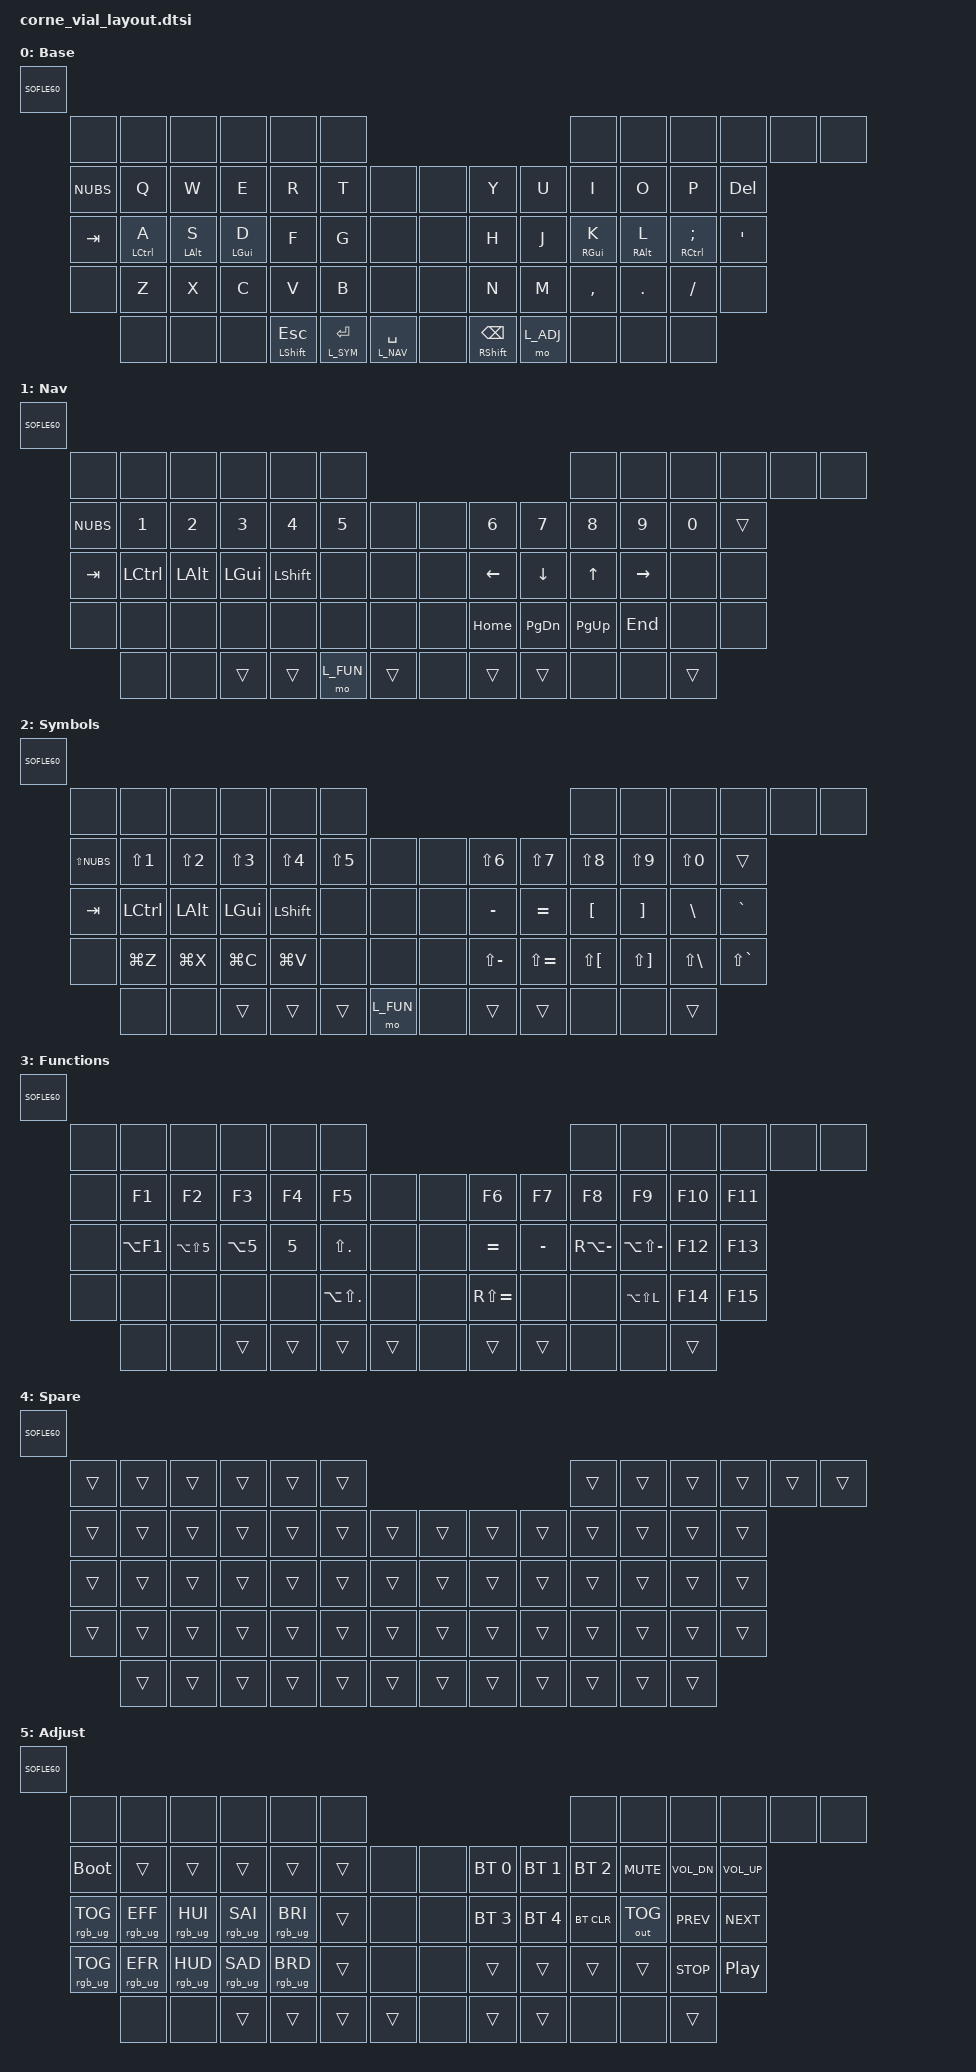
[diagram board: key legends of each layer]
/*
 * Port du keymap Corne 42 Vial (QMK) vers Sofle Choc Pro BT (ZMK).
 * Source : vial-qmk/keyboards/crkbd/keymaps/vial/keymap.c
 *
 * Matrice Sofle 60 avec 42 positions actives (switches Corne) ; le reste en &none.
 * Layout Townk conservé dans standard_layout.dtsi pour y revenir.
 *
 * TODO : réactiver souris — décommenter les includes mouse/homerowmods/specialkeys
 *        et brancher une couche dédiée (absente du Corne Vial par manque de mémoire).
 */

#include <behaviors.dtsi>
#include <dt-bindings/zmk/bt.h>
#include <dt-bindings/zmk/keys.h>
#include <dt-bindings/zmk/outputs.h>
#include <dt-bindings/zmk/rgb.h>

/* #include "specialkeys.dtsi" */
/* #include "homerowmods.dtsi" */
/* #include "mouse.dtsi" */

#define L_BASE  0
#define L_NAV   1
#define L_SYM   2
#define L_FUN   3
#define L_SPARE 4
#define L_ADJ   5

/* TAPPING_TERM Corne Vial = 180 ms */
/ {
  behaviors {
    cmt: corne_mod_tap {
      compatible = "zmk,behavior-hold-tap";
      #binding-cells = <2>;
      flavor = "balanced";
      tapping-term-ms = <180>;
      quick-tap-ms = <180>;
      bindings = <&kp>, <&kp>;
    };

    clt: corne_layer_tap {
      compatible = "zmk,behavior-hold-tap";
      #binding-cells = <2>;
      flavor = "balanced";
      tapping-term-ms = <180>;
      quick-tap-ms = <180>;
      bindings = <&mo>, <&kp>;
    };
  };

  combos {
    compatible = "zmk,combos";

    /* EEPROM Corne : J + K + L → Enter (positions Sofle 31, 32, 33) */
    combo_jkl_enter {
      timeout-ms = <50>;
      key-positions = <31 32 33>;
      layers = <L_BASE>;
      bindings = <&kp RET>;
    };
  };
};

/ {
  keymap {
    compatible = "zmk,keymap";

    /*
     * SOFLE60 : rangée chiffres & HYP & pouces externes → &none.
     * Alpha Corne = rangées lettres/home/bas Sofle ; pouces = K56–K58 | K59,K61,K62.
     */

    BASE {
      display-name = "Base";
      bindings = <SOFLE60(
        &none, &none, &none, &none, &none, &none,                                    &none, &none, &none, &none, &none, &none,
        &kp NUBS, &kp Q, &kp W, &kp E, &kp R, &kp T,    &none, &none,  &kp Y, &kp U, &kp I, &kp O, &kp P, &kp DEL,
        &kp TAB, &cmt LCTRL A, &cmt LALT S, &cmt LGUI D, &kp F, &kp G, &none, &none,  &kp H, &kp J, &cmt RGUI K, &cmt RALT L, &cmt RCTRL SEMI, &kp SQT,
        &none, &kp Z, &kp X, &kp C, &kp V, &kp B,        &none, &none,  &kp N, &kp M, &kp COMMA, &kp DOT, &kp FSLH, &none,
               &none, &none, &none, &cmt LSHFT ESC, &clt L_SYM RET, &clt L_NAV SPACE, &none, &cmt RSHFT BSPC, &mo L_ADJ, &none, &none, &none
      )>;
    };

    NAV {
      display-name = "Nav";
      bindings = <SOFLE60(
        &none, &none, &none, &none, &none, &none,                                    &none, &none, &none, &none, &none, &none,
        &kp NUBS, &kp N1, &kp N2, &kp N3, &kp N4, &kp N5, &none, &none,  &kp N6, &kp N7, &kp N8, &kp N9, &kp N0, &trans,
        &kp TAB, &kp LCTRL, &kp LALT, &kp LGUI, &kp LSHFT, &none, &none, &none,  &kp LEFT, &kp DOWN, &kp UP, &kp RIGHT, &none, &none,
        &none, &none, &none, &none, &none, &none,         &none, &none,  &kp HOME, &kp PG_DN, &kp PG_UP, &kp END, &none, &none,
               &none, &none, &trans, &trans, &mo L_FUN, &trans, &none, &trans, &trans, &none, &none, &trans
      )>;
    };

    SYMBOL {
      display-name = "Symbols";
      bindings = <SOFLE60(
        &none, &none, &none, &none, &none, &none,                                          &none, &none, &none, &none, &none, &none,
        &kp LS(NUBS), &kp LS(N1), &kp LS(N2), &kp LS(N3), &kp LS(N4), &kp LS(N5), &none, &none,  &kp LS(N6), &kp LS(N7), &kp LS(N8), &kp LS(N9), &kp LS(N0), &trans,
        &kp TAB, &kp LCTRL, &kp LALT, &kp LGUI, &kp LSHFT, &none, &none, &none,  &kp MINUS, &kp EQUAL, &kp LBKT, &kp RBKT, &kp BSLH, &kp GRAVE,
        &none, &kp LG(Z), &kp LG(X), &kp LG(C), &kp LG(V), &none, &none, &none,  &kp LS(MINUS), &kp LS(EQUAL), &kp LS(LBKT), &kp LS(RBKT), &kp LS(BSLH), &kp LS(GRAVE),
               &none, &none, &trans, &trans, &trans, &mo L_FUN, &none, &trans, &trans, &none, &none, &trans
      )>;
    };

    FUNCTIONS {
      display-name = "Functions";
      bindings = <SOFLE60(
        &none, &none, &none, &none, &none, &none,                                    &none, &none, &none, &none, &none, &none,
        &none, &kp F1, &kp F2, &kp F3, &kp F4, &kp F5, &none, &none,  &kp F6, &kp F7, &kp F8, &kp F9, &kp F10, &kp F11,
        &none, &kp LA(F1), &kp LA(LS(N5)), &kp LA(N5), &kp N5, &kp LS(DOT), &none, &none,  &kp EQUAL, &kp MINUS, &kp RA(MINUS), &kp LA(LS(MINUS)), &kp F12, &kp F13,
        &none, &none, &none, &none, &none, &kp LA(LS(DOT)), &none, &none,  &kp RS(EQUAL), &none, &none, &kp LA(LS(L)), &kp F14, &kp F15,
               &none, &none, &trans, &trans, &trans, &trans, &none, &trans, &trans, &none, &none, &trans
      )>;
    };

    /* Nom « SPARE » : EMPTY est un macro vide Zephyr (util_macro.h). */
    SPARE {
      display-name = "Spare";
      bindings = <SOFLE60(
        &trans, &trans, &trans, &trans, &trans, &trans,                              &trans, &trans, &trans, &trans, &trans, &trans,
        &trans, &trans, &trans, &trans, &trans, &trans, &trans, &trans,  &trans, &trans, &trans, &trans, &trans, &trans,
        &trans, &trans, &trans, &trans, &trans, &trans, &trans, &trans,  &trans, &trans, &trans, &trans, &trans, &trans,
        &trans, &trans, &trans, &trans, &trans, &trans, &trans, &trans,  &trans, &trans, &trans, &trans, &trans, &trans,
                &trans, &trans, &trans, &trans, &trans, &trans, &trans, &trans, &trans, &trans, &trans, &trans
      )>;
    };

    /* Adjust = Corne L5 (RGB / média / boot) + profils BT (écart wireless minimal) */
    ADJUST {
      display-name = "Adjust";
      bindings = <SOFLE60(
        &none, &none, &none, &none, &none, &none,                                    &none, &none, &none, &none, &none, &none,
        &bootloader, &trans, &trans, &trans, &trans, &trans, &none, &none,  &bt BT_SEL 0, &bt BT_SEL 1, &bt BT_SEL 2, &kp C_MUTE, &kp C_VOL_DN, &kp C_VOL_UP,
        &rgb_ug RGB_TOG, &rgb_ug RGB_EFF, &rgb_ug RGB_HUI, &rgb_ug RGB_SAI, &rgb_ug RGB_BRI, &trans, &none, &none,  &bt BT_SEL 3, &bt BT_SEL 4, &bt BT_CLR, &out OUT_TOG, &kp C_PREV, &kp C_NEXT,
        &rgb_ug RGB_TOG, &rgb_ug RGB_EFR, &rgb_ug RGB_HUD, &rgb_ug RGB_SAD, &rgb_ug RGB_BRD, &trans, &none, &none,  &trans, &trans, &trans, &trans, &kp C_STOP, &kp C_PP,
               &none, &none, &trans, &trans, &trans, &trans, &none, &trans, &trans, &none, &none, &trans
      )>;
    };
  };
};
